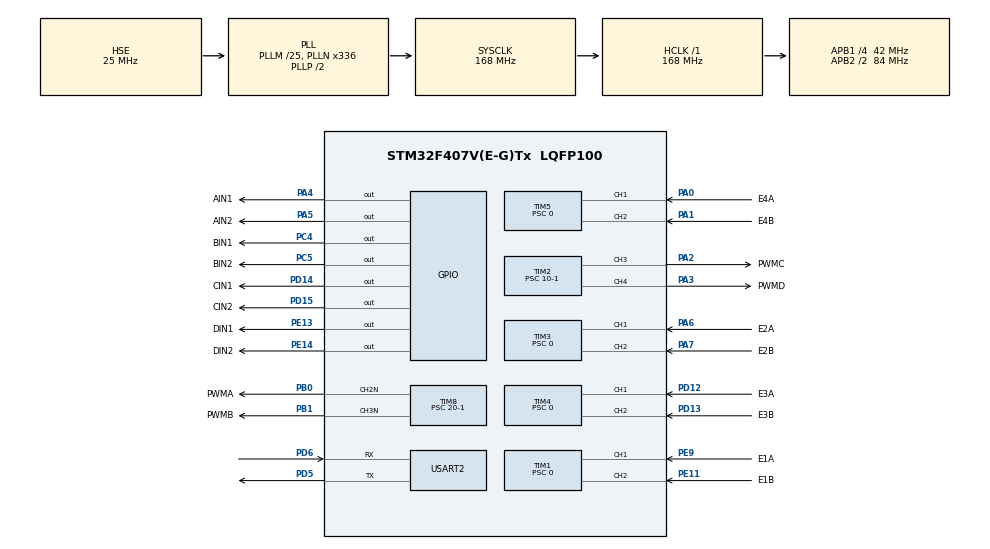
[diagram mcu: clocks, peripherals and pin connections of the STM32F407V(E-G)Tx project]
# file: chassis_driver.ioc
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Dma.Request0=USART2_RX
Dma.Request1=USART2_TX
Dma.USART2_RX.0.Direction=DMA_PERIPH_TO_MEMORY
Dma.USART2_RX.0.FIFOMode=DMA_FIFOMODE_DISABLE
Dma.USART2_RX.0.Instance=DMA1_Stream5
Dma.USART2_RX.0.MemDataAlignment=DMA_MDATAALIGN_BYTE
Dma.USART2_RX.0.MemInc=DMA_MINC_ENABLE
Dma.USART2_RX.0.Mode=DMA_NORMAL
Dma.USART2_RX.0.PeriphDataAlignment=DMA_PDATAALIGN_BYTE
Dma.USART2_RX.0.PeriphInc=DMA_PINC_DISABLE
Dma.USART2_RX.0.Priority=DMA_PRIORITY_LOW
Dma.USART2_TX.1.Direction=DMA_MEMORY_TO_PERIPH
Dma.USART2_TX.1.FIFOMode=DMA_FIFOMODE_DISABLE
Dma.USART2_TX.1.Instance=DMA1_Stream6
Dma.USART2_TX.1.MemDataAlignment=DMA_MDATAALIGN_BYTE
Dma.USART2_TX.1.MemInc=DMA_MINC_ENABLE
Dma.USART2_TX.1.Mode=DMA_NORMAL
Dma.USART2_TX.1.PeriphDataAlignment=DMA_PDATAALIGN_BYTE
Dma.USART2_TX.1.PeriphInc=DMA_PINC_DISABLE
Dma.USART2_TX.1.Priority=DMA_PRIORITY_LOW
FREERTOS.INCLUDE_pcTaskGetTaskName=1
FREERTOS.INCLUDE_uxTaskGetStackHighWaterMark2=1
FREERTOS.INCLUDE_vTaskCleanUpResources=1
FREERTOS.INCLUDE_xEventGroupSetBitFromISR=1
FREERTOS.INCLUDE_xSemaphoreGetMutexHolder=1
FREERTOS.INCLUDE_xTaskAbortDelay=1
FREERTOS.INCLUDE_xTaskGetHandle=1
FREERTOS.Tasks01=defaultTask,24,128,StartDefaultTask,Default,NULL,Dynamic,NULL,NULL
FREERTOS.configENABLE_FPU=1
Mcu.Family=STM32F4
Mcu.Name=STM32F407V(E-G)Tx
Mcu.Package=LQFP100
NVIC.DMA1_Stream5_IRQn=true\:5\:0\:false\:false\:true\:true\:false\:true\:true
NVIC.DMA1_Stream6_IRQn=true\:5\:0\:false\:false\:true\:true\:false\:true\:true
NVIC.PriorityGroup=NVIC_PRIORITYGROUP_4
NVIC.TIM8_TRG_COM_TIM14_IRQn=true\:5\:0\:false\:false\:true\:false\:false\:true\:true
NVIC.TimeBase=TIM8_TRG_COM_TIM14_IRQn
NVIC.TimeBaseIP=TIM14
NVIC.USART2_IRQn=true\:5\:0\:false\:false\:true\:true\:true\:true\:true
PA0-WKUP.GPIO_Label=E4A
PA0-WKUP.Signal=S_TIM5_CH1
PA1.GPIO_Label=E4B
PA1.Signal=S_TIM5_CH2
PA13.Mode=Serial_Wire
PA13.Signal=SYS_JTMS-SWDIO
PA14.Mode=Serial_Wire
PA14.Signal=SYS_JTCK-SWCLK
PA2.GPIO_Label=PWMC
PA2.GPIO_Speed=GPIO_SPEED_FREQ_VERY_HIGH
PA2.Signal=S_TIM2_CH3
PA3.GPIO_Label=PWMD
PA3.GPIO_Speed=GPIO_SPEED_FREQ_VERY_HIGH
PA3.Signal=S_TIM2_CH4
PA4.GPIO_Label=AIN1
PA4.GPIO_Speed=GPIO_SPEED_FREQ_HIGH
PA4.Signal=GPIO_Output
PA5.GPIO_Label=AIN2
PA5.GPIO_Speed=GPIO_SPEED_FREQ_HIGH
PA5.Signal=GPIO_Output
PA6.GPIO_Label=E2A
PA6.Signal=S_TIM3_CH1
PA7.GPIO_Label=E2B
PA7.Signal=S_TIM3_CH2
PB0.GPIO_Label=PWMA
PB0.GPIO_Speed=GPIO_SPEED_FREQ_VERY_HIGH
PB0.Mode=PWM Generation2 CH2N
PB0.Signal=TIM8_CH2N
PB1.GPIO_Label=PWMB
PB1.GPIO_Speed=GPIO_SPEED_FREQ_VERY_HIGH
PB1.Mode=PWM Generation3 CH3N
PB1.Signal=TIM8_CH3N
PC4.GPIO_Label=BIN1
PC4.GPIO_Speed=GPIO_SPEED_FREQ_HIGH
PC4.Signal=GPIO_Output
PC5.GPIO_Label=BIN2
PC5.GPIO_Speed=GPIO_SPEED_FREQ_HIGH
PC5.Signal=GPIO_Output
PD12.GPIO_Label=E3A
PD12.Signal=S_TIM4_CH1
PD13.GPIO_Label=E3B
PD13.Signal=S_TIM4_CH2
PD14.GPIO_Label=CIN1
PD14.GPIO_Speed=GPIO_SPEED_FREQ_HIGH
PD14.Signal=GPIO_Output
PD15.GPIO_Label=CIN2
PD15.GPIO_Speed=GPIO_SPEED_FREQ_HIGH
PD15.Signal=GPIO_Output
PD5.Mode=Asynchronous
PD5.Signal=USART2_TX
PD6.Mode=Asynchronous
PD6.Signal=USART2_RX
PE11.GPIO_Label=E1B
PE11.Signal=S_TIM1_CH2
PE13.GPIO_Label=DIN1
PE13.GPIO_Speed=GPIO_SPEED_FREQ_HIGH
PE13.Signal=GPIO_Output
PE14.GPIO_Label=DIN2
PE14.GPIO_Speed=GPIO_SPEED_FREQ_HIGH
PE14.Signal=GPIO_Output
PE9.GPIO_Label=E1A
PE9.Signal=S_TIM1_CH1
PH0-OSC_IN.Mode=HSE-External-Oscillator
PH0-OSC_IN.Signal=RCC_OSC_IN
PH1-OSC_OUT.Mode=HSE-External-Oscillator
PH1-OSC_OUT.Signal=RCC_OSC_OUT
ProjectManager.HeapSize=0x200
ProjectManager.StackSize=0x400
ProjectManager.TargetToolchain=MDK-ARM V5.32
RCC.48MHZClocksFreq_Value=84000000
RCC.AHBFreq_Value=168000000
RCC.APB1CLKDivider=RCC_HCLK_DIV4
RCC.APB1Freq_Value=42000000
RCC.APB1TimFreq_Value=84000000
RCC.APB2CLKDivider=RCC_HCLK_DIV2
RCC.APB2Freq_Value=84000000
RCC.APB2TimFreq_Value=168000000
RCC.CortexFreq_Value=168000000
RCC.HCLKFreq_Value=168000000
RCC.HSE_VALUE=25000000
RCC.HSI_VALUE=16000000
RCC.LSE_VALUE=32768
RCC.PLLM=25
RCC.PLLN=336
RCC.PLLSourceVirtual=RCC_PLLSOURCE_HSE
RCC.SYSCLKFreq_VALUE=168000000
RCC.SYSCLKSource=RCC_SYSCLKSOURCE_PLLCLK
RCC.VCOOutputFreq_Value=336000000
SH.S_TIM1_CH1.0=TIM1_CH1,Encoder_Interface
SH.S_TIM1_CH2.0=TIM1_CH2,Encoder_Interface
SH.S_TIM2_CH3.0=TIM2_CH3,PWM Generation3 CH3
SH.S_TIM2_CH4.0=TIM2_CH4,PWM Generation4 CH4
SH.S_TIM3_CH1.0=TIM3_CH1,Encoder_Interface
SH.S_TIM3_CH2.0=TIM3_CH2,Encoder_Interface
SH.S_TIM4_CH1.0=TIM4_CH1,Encoder_Interface
SH.S_TIM4_CH2.0=TIM4_CH2,Encoder_Interface
SH.S_TIM5_CH1.0=TIM5_CH1,Encoder_Interface
SH.S_TIM5_CH2.0=TIM5_CH2,Encoder_Interface
TIM1.EncoderMode=TIM_ENCODERMODE_TI12
TIM1.IC1Filter=10
TIM1.IC2Filter=10
TIM1.Period=65535
TIM1.Prescaler=0
TIM2.Channel-PWM\ Generation3\ CH3=TIM_CHANNEL_3
TIM2.Channel-PWM\ Generation4\ CH4=TIM_CHANNEL_4
TIM2.OCFastMode_PWM-PWM\ Generation3\ CH3=TIM_OCFAST_ENABLE
TIM2.OCFastMode_PWM-PWM\ Generation4\ CH4=TIM_OCFAST_ENABLE
TIM2.Period=8400-1
TIM2.Prescaler=10-1
TIM3.EncoderMode=TIM_ENCODERMODE_TI12
TIM3.IC1Filter=10
TIM3.IC2Filter=10
TIM3.Period=65535
TIM3.Prescaler=0
TIM4.EncoderMode=TIM_ENCODERMODE_TI12
TIM4.IC1Filter=10
TIM4.IC2Filter=10
TIM4.Period=65535
TIM4.Prescaler=0
TIM5.EncoderMode=TIM_ENCODERMODE_TI12
TIM5.IC1Filter=10
TIM5.IC2Filter=10
TIM5.Period=65535
TIM5.Prescaler=0
TIM8.Channel-PWM\ Generation2\ CH2N=TIM_CHANNEL_2
TIM8.Channel-PWM\ Generation3\ CH3N=TIM_CHANNEL_3
TIM8.OCFastMode_PWM-PWM\ Generation2\ CH2N=TIM_OCFAST_ENABLE
TIM8.OCFastMode_PWM-PWM\ Generation3\ CH3N=TIM_OCFAST_ENABLE
TIM8.Period=8400-1
TIM8.Prescaler=20-1
USART2.VirtualMode=VM_ASYNC
VP_FREERTOS_VS_CMSIS_V2.Mode=CMSIS_V2
VP_SYS_VS_tim14.Mode=TIM14
VP_TIM2_VS_ClockSourceINT.Mode=Internal
VP_TIM8_VS_ClockSourceINT.Mode=Internal
board=custom

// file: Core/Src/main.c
/* USER CODE BEGIN Header */
/**
  ******************************************************************************
  * @file           : main.c
  * @brief          : Main program body
  ******************************************************************************
  * @attention
  *
  * Copyright (c) 2024 STMicroelectronics.
  * All rights reserved.
  *
  * This software is licensed under terms that can be found in the LICENSE file
  * in the root directory of this software component.
  * If no LICENSE file comes with this software, it is provided AS-IS.
  *
  ******************************************************************************
  */
/* USER CODE END Header */
#include "main.h"
#include "cmsis_os.h"
#include "dma.h"
#include "tim.h"
#include "usart.h"
#include "gpio.h"

/* USER CODE BEGIN Includes */
#include "arm_math.h"
/* USER CODE END Includes */

void SystemClock_Config(void);
void MX_FREERTOS_Init(void);

int main(void)
{

  /* MCU Configuration--------------------------------------------------------*/

  /* Reset of all peripherals, Initializes the Flash interface and the Systick. */
  HAL_Init();

  /* Configure the system clock */
  SystemClock_Config();

  /* Initialize all configured peripherals */
  MX_GPIO_Init();
  MX_DMA_Init();
  MX_TIM5_Init();
  MX_TIM1_Init();
  MX_TIM3_Init();
  MX_TIM4_Init();
  MX_TIM2_Init();
  MX_TIM8_Init();
  MX_USART2_UART_Init();

  /* Init scheduler */
  osKernelInitialize();  /* Call init function for freertos objects (in freertos.c) */
  MX_FREERTOS_Init();

  /* Start scheduler */
  osKernelStart();

  /* We should never get here as control is now taken by the scheduler */
  /* Infinite loop */
  while (1)
  {

  }
}

void SystemClock_Config(void)
{
  RCC_OscInitTypeDef RCC_OscInitStruct = {0};
  RCC_ClkInitTypeDef RCC_ClkInitStruct = {0};

  /** Configure the main internal regulator output voltage
  */
  __HAL_RCC_PWR_CLK_ENABLE();
  __HAL_PWR_VOLTAGESCALING_CONFIG(PWR_REGULATOR_VOLTAGE_SCALE1);

  /** Initializes the RCC Oscillators according to the specified parameters
  * in the RCC_OscInitTypeDef structure.
  */
  RCC_OscInitStruct.OscillatorType = RCC_OSCILLATORTYPE_HSE;
  RCC_OscInitStruct.HSEState = RCC_HSE_ON;
  RCC_OscInitStruct.PLL.PLLState = RCC_PLL_ON;
  RCC_OscInitStruct.PLL.PLLSource = RCC_PLLSOURCE_HSE;
  RCC_OscInitStruct.PLL.PLLM = 25;
  RCC_OscInitStruct.PLL.PLLN = 336;
  RCC_OscInitStruct.PLL.PLLP = RCC_PLLP_DIV2;
  RCC_OscInitStruct.PLL.PLLQ = 4;
  if (HAL_RCC_OscConfig(&RCC_OscInitStruct) != HAL_OK)
  {
    Error_Handler();
  }

  /** Initializes the CPU, AHB and APB buses clocks
  */
  RCC_ClkInitStruct.ClockType = RCC_CLOCKTYPE_HCLK|RCC_CLOCKTYPE_SYSCLK
                              |RCC_CLOCKTYPE_PCLK1|RCC_CLOCKTYPE_PCLK2;
  RCC_ClkInitStruct.SYSCLKSource = RCC_SYSCLKSOURCE_PLLCLK;
  RCC_ClkInitStruct.AHBCLKDivider = RCC_SYSCLK_DIV1;
  RCC_ClkInitStruct.APB1CLKDivider = RCC_HCLK_DIV4;
  RCC_ClkInitStruct.APB2CLKDivider = RCC_HCLK_DIV2;

  if (HAL_RCC_ClockConfig(&RCC_ClkInitStruct, FLASH_LATENCY_5) != HAL_OK)
  {
    Error_Handler();
  }
}

void HAL_TIM_PeriodElapsedCallback(TIM_HandleTypeDef *htim)
{
  if (htim->Instance == TIM14) {
    HAL_IncTick();
  }
}

void Error_Handler(void)
{
  __disable_irq();
  while (1)
  {
  }
}

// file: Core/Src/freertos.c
/* USER CODE BEGIN Header */
/**
  ******************************************************************************
  * File Name          : freertos.c
  * Description        : Code for freertos applications
  ******************************************************************************
  * @attention
  *
  * Copyright (c) 2024 STMicroelectronics.
  * All rights reserved.
  *
  * This software is licensed under terms that can be found in the LICENSE file
  * in the root directory of this software component.
  * If no LICENSE file comes with this software, it is provided AS-IS.
  *
  ******************************************************************************
  */
/* USER CODE END Header */

#include "FreeRTOS.h"
#include "task.h"
#include "main.h"
#include "cmsis_os.h"

/* USER CODE BEGIN Includes */
#include "master.h"
/* USER CODE END Includes */

/* Definitions for defaultTask */
osThreadId_t defaultTaskHandle;
const osThreadAttr_t defaultTask_attributes = {
  .name = "defaultTask",
  .stack_size = 128 * 4,
  .priority = (osPriority_t) osPriorityNormal,
};

void StartDefaultTask(void *argument);

void MX_FREERTOS_Init(void); /* (MISRA C 2004 rule 8.1) */

void MX_FREERTOS_Init(void) {

  /* Create the thread(s) */
  /* creation of defaultTask */
  defaultTaskHandle = osThreadNew(StartDefaultTask, NULL, &defaultTask_attributes);

  /* USER CODE BEGIN RTOS_THREADS */
	master_init();
  /* add threads, ... */
  /* USER CODE END RTOS_THREADS */

}

void StartDefaultTask(void *argument)
{
  /* USER CODE BEGIN StartDefaultTask */
  /* Infinite loop */
	vTaskDelete(NULL);
  for(;;)
  {
    osDelay(1);
  }
  /* USER CODE END StartDefaultTask */
}
